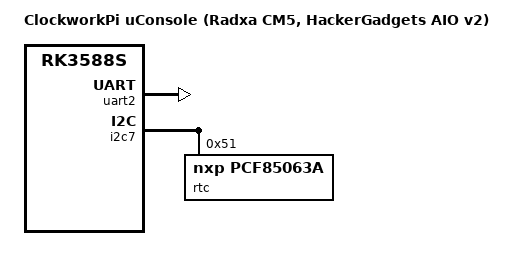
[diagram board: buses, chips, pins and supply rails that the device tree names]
// SPDX-License-Identifier: (GPL-2.0+ OR MIT)
/*
 * ClockworkPi uConsole + Radxa CM5 with the HackerGadgets AIO v2 expansion board.
 *
 * Variant of rk3588s-radxa-cm5-uconsole.dts: everything from the base file
 * applies. This file adds only the AIO itself; the rest comes from includes
 * that are useful without an AIO too:
 *
 *   rk3588s-radxa-cm5-uconsole-mainboard.dtsi   OCP8178 backlight (32 levels,
 *                                               needs CONFIG_BACKLIGHT_OCP8178),
 *                                               amplifier enable held low, no
 *                                               UART4 console
 *   rk3588s-radxa-cm5-uconsole-hg-fan.dtsi      the HackerGadgets adapter's fan
 *                                               header as a pwm-fan
 *   rk3588s-radxa-cm5-uconsole-battery-10ah.dtsi  labels for THIS fork's 10 Ah
 *                                               cell; per machine, swap or drop
 *
 * The AIO part, see docs/aio-v2.md:
 *  - UART2 (uart2m0, GPIO0_B5/B6 = CM4 socket pins 8/10) for the AIO GPS -> /dev/ttyS2
 *  - I2C7 (i2c7m2, GPIO3_D2/D3 = the CM4 SDA0/SCL0 pair = the only I2C on the
 *    uConsole's mPCIe slot) with the AIO's PCF85063A RTC at 0x51 -> /dev/rtc0
 *  - SPI4 is deliberately NOT enabled. The AIO's LoRa SX1262 sits on those
 *    lines, but its MISO ends on a module position the Radxa CM5 leaves
 *    unconnected (HackerGadgets' schematics, measured; docs/aio-v2.md), and
 *    with ClockworkPi's 4G board in the slot the same lines carry the modem's
 *    PCM interface: an enabled SPI4 would drive its clock and chip select
 *    against the modem's outputs. With the one-wire fix (MISO to the AIO's TP2
 *    -> GPIO1_C2) use rk3588s-radxa-cm5-uconsole-aio-lora.dts instead, which
 *    includes this file and adds an spi-gpio bus.
 *
 * tools/patch-uconsole-dtb.py produces the same AIO nodes (plus the battery
 * labels) from a prebuilt base DTB, without a kernel tree.
 */

#include "rk3588s-radxa-cm5-uconsole.dts"
#include "rk3588s-radxa-cm5-uconsole-mainboard.dtsi"
#include "rk3588s-radxa-cm5-uconsole-hg-fan.dtsi"
#include "rk3588s-radxa-cm5-uconsole-battery-10ah.dtsi"

/ {
	model = "ClockworkPi uConsole (Radxa CM5, HackerGadgets AIO v2)";
};

/* AIO GPS on the mainboard's Pi UART0 lines (socket pins 8/10). */
&uart2 {
	pinctrl-names = "default";
	pinctrl-0 = <&uart2m0_xfer>;
	status = "okay";
};

/* The mPCIe slot's I2C: mainboard nets GPIO44/45 = CM4 SDA0/SCL0 = Connector 1
 * positions 82/80 = GPIO3_D3/D2 on the CM5. The AIO RTC (PCF85063A) sits here. */
&i2c7 {
	pinctrl-names = "default";
	pinctrl-0 = <&i2c7m2_xfer>;
	status = "okay";

	rtc@51 {
		compatible = "nxp,pcf85063a";
		reg = <0x51>;
	};
};
